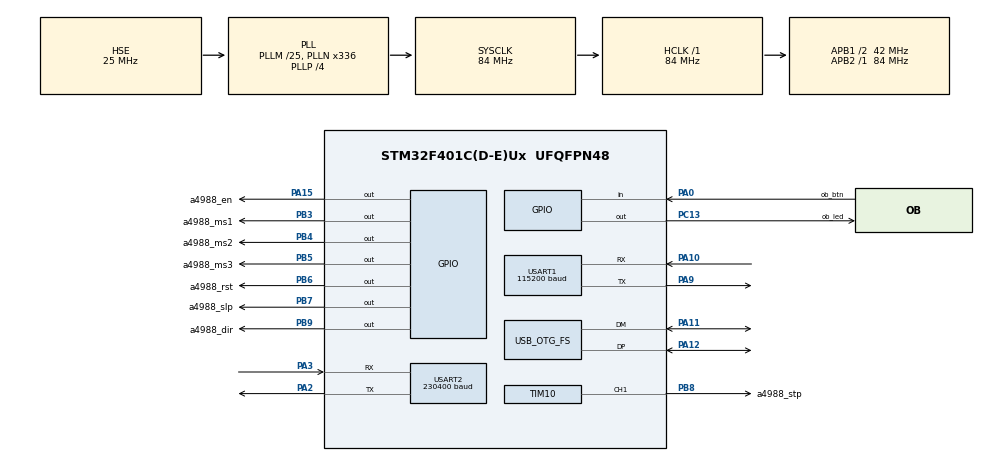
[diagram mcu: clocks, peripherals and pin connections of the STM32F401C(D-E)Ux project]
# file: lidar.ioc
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Dma.Request0=USART1_RX
Dma.Request1=USART1_TX
Dma.Request2=USART2_RX
Dma.Request3=USART2_TX
Dma.USART1_RX.0.Direction=DMA_PERIPH_TO_MEMORY
Dma.USART1_RX.0.FIFOMode=DMA_FIFOMODE_DISABLE
Dma.USART1_RX.0.Instance=DMA2_Stream2
Dma.USART1_RX.0.MemDataAlignment=DMA_MDATAALIGN_BYTE
Dma.USART1_RX.0.MemInc=DMA_MINC_ENABLE
Dma.USART1_RX.0.Mode=DMA_CIRCULAR
Dma.USART1_RX.0.PeriphDataAlignment=DMA_PDATAALIGN_BYTE
Dma.USART1_RX.0.PeriphInc=DMA_PINC_DISABLE
Dma.USART1_RX.0.Priority=DMA_PRIORITY_LOW
Dma.USART1_TX.1.Direction=DMA_MEMORY_TO_PERIPH
Dma.USART1_TX.1.FIFOMode=DMA_FIFOMODE_DISABLE
Dma.USART1_TX.1.Instance=DMA2_Stream7
Dma.USART1_TX.1.MemDataAlignment=DMA_MDATAALIGN_BYTE
Dma.USART1_TX.1.MemInc=DMA_MINC_ENABLE
Dma.USART1_TX.1.Mode=DMA_NORMAL
Dma.USART1_TX.1.PeriphDataAlignment=DMA_PDATAALIGN_BYTE
Dma.USART1_TX.1.PeriphInc=DMA_PINC_DISABLE
Dma.USART1_TX.1.Priority=DMA_PRIORITY_LOW
Dma.USART2_RX.2.Direction=DMA_PERIPH_TO_MEMORY
Dma.USART2_RX.2.FIFOMode=DMA_FIFOMODE_DISABLE
Dma.USART2_RX.2.Instance=DMA1_Stream5
Dma.USART2_RX.2.MemDataAlignment=DMA_MDATAALIGN_BYTE
Dma.USART2_RX.2.MemInc=DMA_MINC_ENABLE
Dma.USART2_RX.2.Mode=DMA_CIRCULAR
Dma.USART2_RX.2.PeriphDataAlignment=DMA_PDATAALIGN_BYTE
Dma.USART2_RX.2.PeriphInc=DMA_PINC_DISABLE
Dma.USART2_RX.2.Priority=DMA_PRIORITY_LOW
Dma.USART2_TX.3.Direction=DMA_MEMORY_TO_PERIPH
Dma.USART2_TX.3.FIFOMode=DMA_FIFOMODE_DISABLE
Dma.USART2_TX.3.Instance=DMA1_Stream6
Dma.USART2_TX.3.MemDataAlignment=DMA_MDATAALIGN_BYTE
Dma.USART2_TX.3.MemInc=DMA_MINC_ENABLE
Dma.USART2_TX.3.Mode=DMA_NORMAL
Dma.USART2_TX.3.PeriphDataAlignment=DMA_PDATAALIGN_BYTE
Dma.USART2_TX.3.PeriphInc=DMA_PINC_DISABLE
Dma.USART2_TX.3.Priority=DMA_PRIORITY_LOW
FREERTOS.INCLUDE_vTaskDelayUntil=1
FREERTOS.Tasks01=defaultTask,0,128,StartDefaultTask,Default,NULL,Dynamic,NULL,NULL
FREERTOS.configUSE_NEWLIB_REENTRANT=1
Mcu.Family=STM32F4
Mcu.Name=STM32F401C(D-E)Ux
Mcu.Package=UFQFPN48
NVIC.DMA1_Stream5_IRQn=true\:5\:0\:false\:false\:true\:true\:false\:true\:true
NVIC.DMA1_Stream6_IRQn=true\:5\:0\:false\:false\:true\:true\:false\:true\:true
NVIC.DMA2_Stream2_IRQn=true\:5\:0\:false\:false\:true\:true\:false\:true\:true
NVIC.DMA2_Stream7_IRQn=true\:5\:0\:false\:false\:true\:true\:false\:true\:true
NVIC.OTG_FS_IRQn=true\:5\:0\:false\:false\:true\:true\:true\:true\:true
NVIC.PriorityGroup=NVIC_PRIORITYGROUP_4
NVIC.TIM1_UP_TIM10_IRQn=true\:5\:0\:false\:false\:true\:false\:false\:true\:true
NVIC.TIM2_IRQn=true\:15\:0\:false\:false\:true\:false\:false\:true\:true
NVIC.TimeBase=TIM2_IRQn
NVIC.TimeBaseIP=TIM2
NVIC.USART1_IRQn=true\:5\:0\:false\:false\:true\:true\:true\:true\:true
NVIC.USART2_IRQn=true\:5\:0\:false\:false\:true\:true\:true\:true\:true
PA0-WKUP.GPIO_Label=ob_btn
PA0-WKUP.Signal=GPIO_Input
PA10.Mode=Asynchronous
PA10.Signal=USART1_RX
PA11.Mode=Device_Only
PA11.Signal=USB_OTG_FS_DM
PA12.Mode=Device_Only
PA12.Signal=USB_OTG_FS_DP
PA13.Mode=Serial_Wire
PA13.Signal=SYS_JTMS-SWDIO
PA14.Mode=Serial_Wire
PA14.Signal=SYS_JTCK-SWCLK
PA15.GPIO_Label=a4988_en
PA15.Signal=GPIO_Output
PA2.Mode=Asynchronous
PA2.Signal=USART2_TX
PA3.Mode=Asynchronous
PA3.Signal=USART2_RX
PA9.Mode=Asynchronous
PA9.Signal=USART1_TX
PB3.GPIO_Label=a4988_ms1
PB3.Signal=GPIO_Output
PB4.GPIO_Label=a4988_ms2
PB4.Signal=GPIO_Output
PB5.GPIO_Label=a4988_ms3
PB5.Signal=GPIO_Output
PB6.GPIO_Label=a4988_rst
PB6.GPIO_PuPd=GPIO_PULLUP
PB6.PinState=GPIO_PIN_RESET
PB6.Signal=GPIO_Output
PB7.GPIO_Label=a4988_slp
PB7.GPIO_PuPd=GPIO_PULLUP
PB7.PinState=GPIO_PIN_RESET
PB7.Signal=GPIO_Output
PB8.GPIO_Label=a4988_stp
PB8.Signal=S_TIM10_CH1
PB9.GPIO_Label=a4988_dir
PB9.Signal=GPIO_Output
PC13-ANTI_TAMP.GPIO_Label=ob_led
PC13-ANTI_TAMP.Signal=GPIO_Output
PH0\ -\ OSC_IN.Mode=HSE-External-Oscillator
PH0\ -\ OSC_IN.Signal=RCC_OSC_IN
PH1\ -\ OSC_OUT.Mode=HSE-External-Oscillator
PH1\ -\ OSC_OUT.Signal=RCC_OSC_OUT
ProjectManager.HeapSize=0x200
ProjectManager.StackSize=0x400
ProjectManager.TargetToolchain=STM32CubeIDE
RCC.48MHZClocksFreq_Value=48000000
RCC.AHBFreq_Value=84000000
RCC.APB1CLKDivider=RCC_HCLK_DIV2
RCC.APB1Freq_Value=42000000
RCC.APB1TimFreq_Value=84000000
RCC.APB2Freq_Value=84000000
RCC.APB2TimFreq_Value=84000000
RCC.CortexFreq_Value=84000000
RCC.HCLKFreq_Value=84000000
RCC.HSE_VALUE=25000000
RCC.HSI_VALUE=16000000
RCC.LSE_VALUE=32768
RCC.PLLM=25
RCC.PLLN=336
RCC.PLLP=RCC_PLLP_DIV4
RCC.PLLQ=7
RCC.SYSCLKFreq_VALUE=84000000
RCC.SYSCLKSource=RCC_SYSCLKSOURCE_PLLCLK
RCC.VCOOutputFreq_Value=336000000
SH.S_TIM10_CH1.0=TIM10_CH1,PWM Generation1 CH1
TIM10.Channel=TIM_CHANNEL_1
TIM10.OC1Preload_PWM=ENABLE
TIM10.Period=1
TIM10.Prescaler=83
TIM10.Pulse=32768
USART1.BaudRate=115200
USART1.VirtualMode=VM_ASYNC
USART2.BaudRate=230400
USART2.VirtualMode=VM_ASYNC
USB_DEVICE.CLASS_NAME_FS=CDC
USB_DEVICE.VirtualMode-CDC_FS=Cdc
USB_DEVICE.VirtualModeFS=Cdc_FS
USB_OTG_FS.VirtualMode=Device_Only
VP_FREERTOS_VS_CMSIS_V1.Mode=CMSIS_V1
VP_SYS_VS_tim2.Mode=TIM2
VP_TIM10_VS_ClockSourceINT.Mode=Enable_Timer
VP_USB_DEVICE_VS_USB_DEVICE_CDC_FS.Mode=CDC_FS
board=custom

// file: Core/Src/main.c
/* USER CODE BEGIN Header */
/**
  ******************************************************************************
  * @file           : main.c
  * @brief          : Main program body
  ******************************************************************************
  * @attention
  *
  * Copyright (c) 2023 STMicroelectronics.
  * All rights reserved.
  *
  * This software is licensed under terms that can be found in the LICENSE file
  * in the root directory of this software component.
  * If no LICENSE file comes with this software, it is provided AS-IS.
  *
  ******************************************************************************
  */
/* USER CODE END Header */
#include "main.h"
#include "cmsis_os.h"
#include "dma.h"
#include "tim.h"
#include "usart.h"
#include "usb_device.h"
#include "gpio.h"

void SystemClock_Config(void);
void MX_FREERTOS_Init(void);

int main(void)
{

  /* MCU Configuration--------------------------------------------------------*/

  /* Reset of all peripherals, Initializes the Flash interface and the Systick. */
  HAL_Init();

  /* Configure the system clock */
  SystemClock_Config();

  /* Initialize all configured peripherals */
  MX_GPIO_Init();
  MX_DMA_Init();
  MX_USART1_UART_Init();
  MX_USART2_UART_Init();
  MX_TIM10_Init();
  /* USER CODE BEGIN 2 */
#if 0
  /* USER CODE END 2 */

  /* Call init function for freertos objects (in freertos.c) */
  MX_FREERTOS_Init();

  /* Start scheduler */
  osKernelStart();

  /* We should never get here as control is now taken by the scheduler */
  /* Infinite loop */
  /* USER CODE BEGIN WHILE */
#endif
  vTaskStartScheduler();
  while (1)
  {
	  /*!!!! Warning !!!!
	   * This code designed as a freertos C++ project.
	   * Projects tasks in freertos_space/tasks.cpp source file.
	   * Enjoy reviewing code <3
	   * */
    /* USER CODE END WHILE */

  }
}

void SystemClock_Config(void)
{
  RCC_OscInitTypeDef RCC_OscInitStruct = {0};
  RCC_ClkInitTypeDef RCC_ClkInitStruct = {0};

  /** Configure the main internal regulator output voltage
  */
  __HAL_RCC_PWR_CLK_ENABLE();
  __HAL_PWR_VOLTAGESCALING_CONFIG(PWR_REGULATOR_VOLTAGE_SCALE2);

  /** Initializes the RCC Oscillators according to the specified parameters
  * in the RCC_OscInitTypeDef structure.
  */
  RCC_OscInitStruct.OscillatorType = RCC_OSCILLATORTYPE_HSE;
  RCC_OscInitStruct.HSEState = RCC_HSE_ON;
  RCC_OscInitStruct.PLL.PLLState = RCC_PLL_ON;
  RCC_OscInitStruct.PLL.PLLSource = RCC_PLLSOURCE_HSE;
  RCC_OscInitStruct.PLL.PLLM = 25;
  RCC_OscInitStruct.PLL.PLLN = 336;
  RCC_OscInitStruct.PLL.PLLP = RCC_PLLP_DIV4;
  RCC_OscInitStruct.PLL.PLLQ = 7;
  if (HAL_RCC_OscConfig(&RCC_OscInitStruct) != HAL_OK)
  {
    Error_Handler();
  }

  /** Initializes the CPU, AHB and APB buses clocks
  */
  RCC_ClkInitStruct.ClockType = RCC_CLOCKTYPE_HCLK|RCC_CLOCKTYPE_SYSCLK
                              |RCC_CLOCKTYPE_PCLK1|RCC_CLOCKTYPE_PCLK2;
  RCC_ClkInitStruct.SYSCLKSource = RCC_SYSCLKSOURCE_PLLCLK;
  RCC_ClkInitStruct.AHBCLKDivider = RCC_SYSCLK_DIV1;
  RCC_ClkInitStruct.APB1CLKDivider = RCC_HCLK_DIV2;
  RCC_ClkInitStruct.APB2CLKDivider = RCC_HCLK_DIV1;

  if (HAL_RCC_ClockConfig(&RCC_ClkInitStruct, FLASH_LATENCY_2) != HAL_OK)
  {
    Error_Handler();
  }
}

void HAL_TIM_PeriodElapsedCallback(TIM_HandleTypeDef *htim)
{
  if (htim->Instance == TIM2) {
    HAL_IncTick();
  }
}

void Error_Handler(void)
{
  __disable_irq();
  while (1)
  {
  }
}
